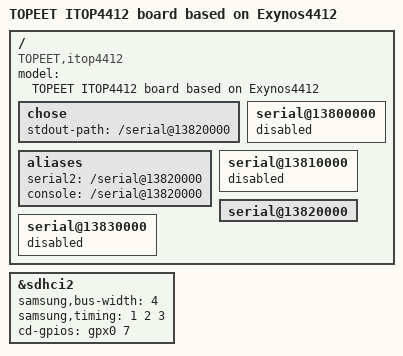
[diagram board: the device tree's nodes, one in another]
// SPDX-License-Identifier: GPL-2.0+
/*
 * refer to exynos4210-origen.dts
 *
 * Samsung's Exynos4412 based iTOP4412 board device tree source
 *
 * Copyright (c) 2018 Wang Xinlu <wangkartx@gmail.com>
 *
 */

/dts-v1/;
#include "exynos4412.dtsi"

/ {
	model = "TOPEET ITOP4412 board based on Exynos4412";
	compatible = "TOPEET,itop4412", "samsung,exynos4412";

    chose {
        stdout-path = "/serial@13820000";
    };

	aliases {
		serial2 = "/serial@13820000";
		console = "/serial@13820000";
	};

    serial@13800000 {
        status = "disabled";
    };

    serial@13810000 {
        status = "disabled";
    };

    serial@13820000 {
        status = "okay";
    };

    serial@13830000 {
        status = "disabled";
    };
};

&sdhci2 {
	samsung,bus-width = <4>;
	samsung,timing = <1 2 3>;
	cd-gpios = <&gpx0 7 0>;
	status = "okay";
};
